# N32MC47x_DP47x register map
Vendor: Nsingtech Ltd.; File version: 1.0
Registers are 32-bit, read-write, reset 0x0 unless marked. A register's access mark holds for its fields unless they carry their own. Offsets are from the block's base; [hi:lo] are bit positions.

## USART1
Base 0x40011C00
Same registers: USART2 0x40000C00, USART3 0x40001000, UART8 0x40001400, UART5 0x40006800, UART6 0x40012000, UART7 0x40012400, USART4 0x40012800
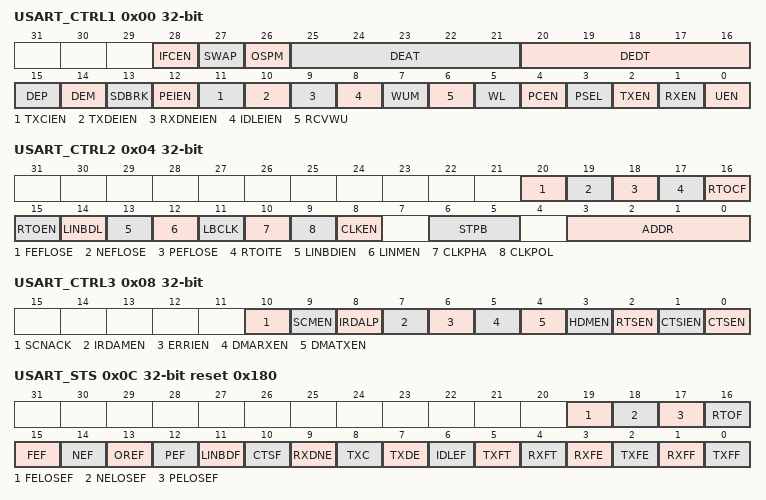
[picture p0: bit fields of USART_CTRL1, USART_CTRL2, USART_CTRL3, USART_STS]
0x00 USART_CTRL1
  [28] IFCEN, [27] SWAP, [26] OSPM, [25:21] DEAT, [20:16] DEDT, [15] DEP, [14] DEM, [13] SDBRK, [12] PEIEN, [11] TXCIEN, [10] TXDEIEN, [9] RXDNEIEN, [8] IDLEIEN, [7] WUM, [6] RCVWU, [5] WL, [4] PCEN, [3] PSEL, [2] TXEN, [1] RXEN, [0] UEN
0x04 USART_CTRL2
  [20] FEFLOSE, [19] NEFLOSE, [18] PEFLOSE, [17] RTOITE, [16] RTOCF, [15] RTOEN, [14] LINBDL, [13] LINBDIEN, [12] LINMEN, [11] LBCLK, [10] CLKPHA, [9] CLKPOL, [8] CLKEN, [6:5] STPB, [3:0] ADDR
0x08 USART_CTRL3
  [10] SCNACK, [9] SCMEN, [8] IRDALP, [7] IRDAMEN, [6] ERRIEN, [5] DMARXEN, [4] DMATXEN, [3] HDMEN, [2] RTSEN, [1] CTSIEN, [0] CTSEN
0x0C USART_STS reset 0x180
  [19] FELOSEF, [18] NELOSEF, [17] PELOSEF, [16] RTOF, [15] FEF, [14] NEF, [13] OREF, [12] PEF, [11] LINBDF, [10] CTSF, [9] RXDNE, [8] TXC, [7] TXDE, [6] IDLEF, [5] TXFT, [4] RXFT, [3] RXFE, [2] TXFE, [1] RXFF, [0] TXFF
0x10 USART_DAT
  [8:0] DATV
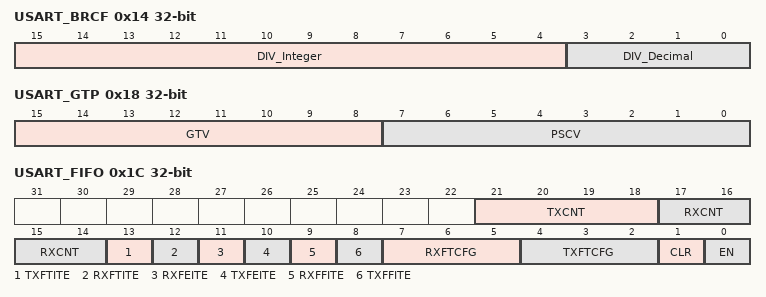
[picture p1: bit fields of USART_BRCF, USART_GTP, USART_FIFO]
0x14 USART_BRCF
  [15:4] DIV_Integer, [3:0] DIV_Decimal
0x18 USART_GTP
  [15:8] GTV, [7:0] PSCV
0x1C USART_FIFO
  [21:18] TXCNT, [17:14] RXCNT, [13] TXFTITE, [12] RXFTITE, [11] RXFEITE, [10] TXFEITE, [9] RXFFITE, [8] TXFFITE, [7:5] RXFTCFG, [4:2] TXFTCFG, [1] CLR, [0] EN
0x20 USART_IFW
  [15:0] WIDTH
0x24 USART_RTO
  [27:0] TIME

## DAC12
Base 0x40007C00
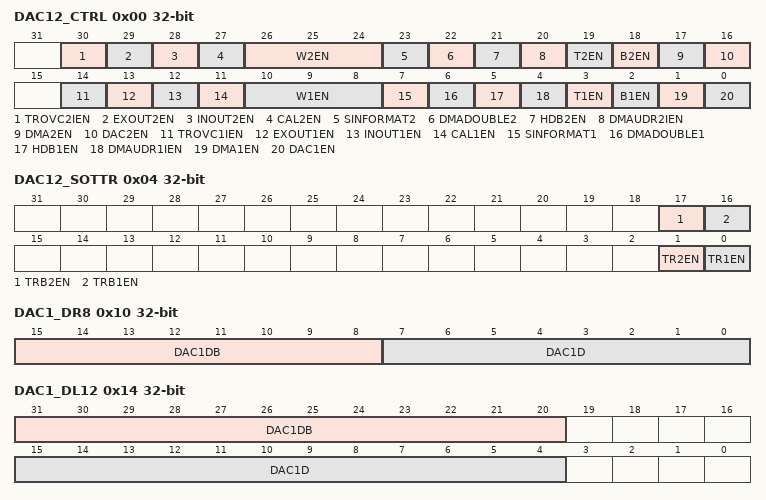
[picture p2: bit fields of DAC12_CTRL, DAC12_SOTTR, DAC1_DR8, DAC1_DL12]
0x00 DAC12_CTRL
  [30] TROVC2IEN, [29] EXOUT2EN, [28] INOUT2EN, [27] CAL2EN, [26:24] W2EN, [23] SINFORMAT2, [22] DMADOUBLE2, [21] HDB2EN, [20] DMAUDR2IEN, [19] T2EN, [18] B2EN, [17] DMA2EN, [16] DAC2EN, [14] TROVC1IEN, [13] EXOUT1EN, [12] INOUT1EN, [11] CAL1EN, [10:8] W1EN, [7] SINFORMAT1, [6] DMADOUBLE1, [5] HDB1EN, [4] DMAUDR1IEN, [3] T1EN, [2] B1EN, [1] DMA1EN, [0] DAC1EN
0x04 DAC12_SOTTR
  [17] TRB2EN, [16] TRB1EN, [1] TR2EN, [0] TR1EN
0x08 DAC1_DATO
  [11:0] DAC1DO
0x0C DAC2_DATO
  [11:0] DAC2DO
0x10 DAC1_DR8
  [15:8] DAC1DB, [7:0] DAC1D
0x14 DAC1_DL12
  [31:20] DAC1DB, [15:4] DAC1D
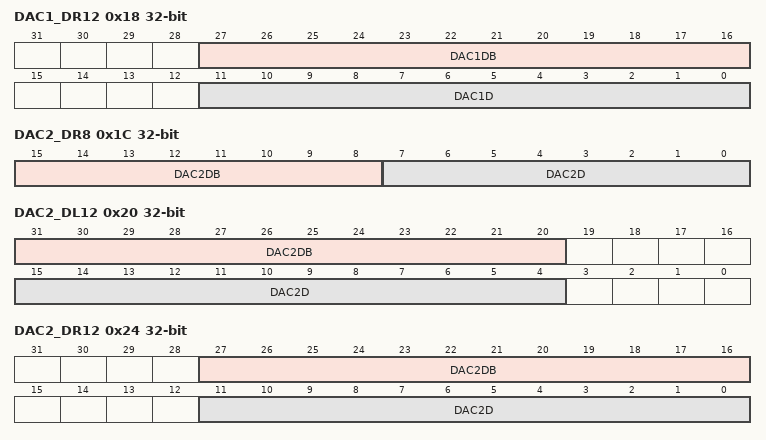
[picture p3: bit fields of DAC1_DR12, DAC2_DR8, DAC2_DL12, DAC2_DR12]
0x18 DAC1_DR12
  [27:16] DAC1DB, [11:0] DAC1D
0x1C DAC2_DR8
  [15:8] DAC2DB, [7:0] DAC2D
0x20 DAC2_DL12
  [31:20] DAC2DB, [15:4] DAC2D
0x24 DAC2_DR12
  [27:16] DAC2DB, [11:0] DAC2D
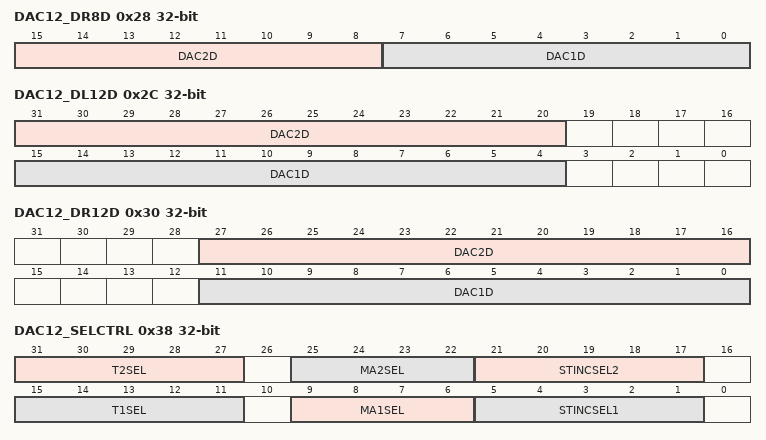
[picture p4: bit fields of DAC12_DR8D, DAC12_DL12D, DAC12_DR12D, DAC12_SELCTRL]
0x28 DAC12_DR8D
  [15:8] DAC2D, [7:0] DAC1D
0x2C DAC12_DL12D
  [31:20] DAC2D, [15:4] DAC1D
0x30 DAC12_DR12D
  [27:16] DAC2D, [11:0] DAC1D
0x38 DAC12_SELCTRL
  [31:27] T2SEL, [25:22] MA2SEL, [21:17] STINCSEL2, [15:11] T1SEL, [9:6] MA1SEL, [5:1] STINCSEL1
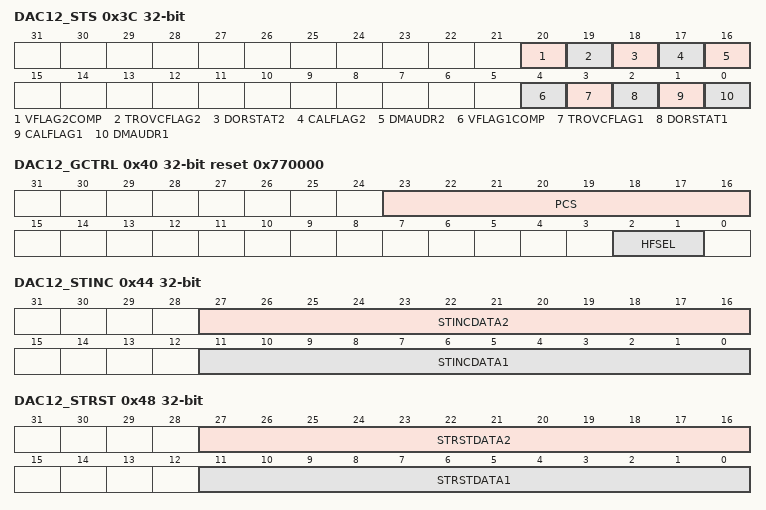
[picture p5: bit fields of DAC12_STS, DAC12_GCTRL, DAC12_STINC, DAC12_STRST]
0x3C DAC12_STS
  [20] VFLAG2COMP, [19] TROVCFLAG2, [18] DORSTAT2, [17] CALFLAG2, [16] DMAUDR2, [4] VFLAG1COMP, [3] TROVCFLAG1, [2] DORSTAT1, [1] CALFLAG1, [0] DMAUDR1
0x40 DAC12_GCTRL reset 0x770000
  [23:16] PCS, [2:1] HFSEL
0x44 DAC12_STINC
  [27:16] STINCDATA2, [11:0] STINCDATA1
0x48 DAC12_STRST
  [27:16] STRSTDATA2, [11:0] STRSTDATA1
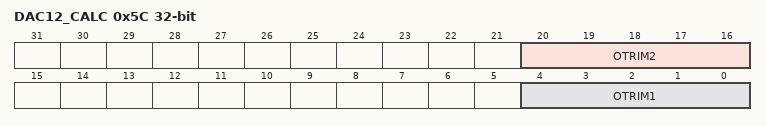
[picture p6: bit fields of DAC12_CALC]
0x5C DAC12_CALC
  [20:16] OTRIM2, [4:0] OTRIM1

## DAC34
Base 0x40008000
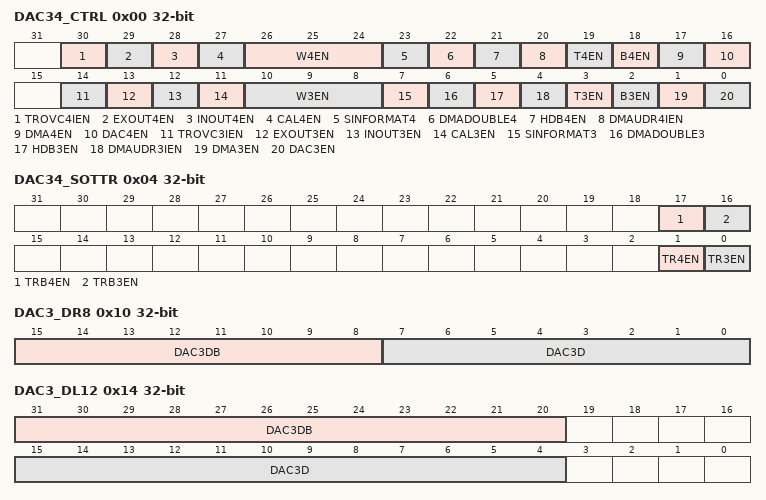
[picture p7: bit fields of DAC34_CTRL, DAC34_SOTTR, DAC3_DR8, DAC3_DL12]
0x00 DAC34_CTRL
  [30] TROVC4IEN, [29] EXOUT4EN, [28] INOUT4EN, [27] CAL4EN, [26:24] W4EN, [23] SINFORMAT4, [22] DMADOUBLE4, [21] HDB4EN, [20] DMAUDR4IEN, [19] T4EN, [18] B4EN, [17] DMA4EN, [16] DAC4EN, [14] TROVC3IEN, [13] EXOUT3EN, [12] INOUT3EN, [11] CAL3EN, [10:8] W3EN, [7] SINFORMAT3, [6] DMADOUBLE3, [5] HDB3EN, [4] DMAUDR3IEN, [3] T3EN, [2] B3EN, [1] DMA3EN, [0] DAC3EN
0x04 DAC34_SOTTR
  [17] TRB4EN, [16] TRB3EN, [1] TR4EN, [0] TR3EN
0x08 DAC3_DATO
  [11:0] DAC3DO
0x0C DAC4_DATO
  [11:0] DAC4DO
0x10 DAC3_DR8
  [15:8] DAC3DB, [7:0] DAC3D
0x14 DAC3_DL12
  [31:20] DAC3DB, [15:4] DAC3D
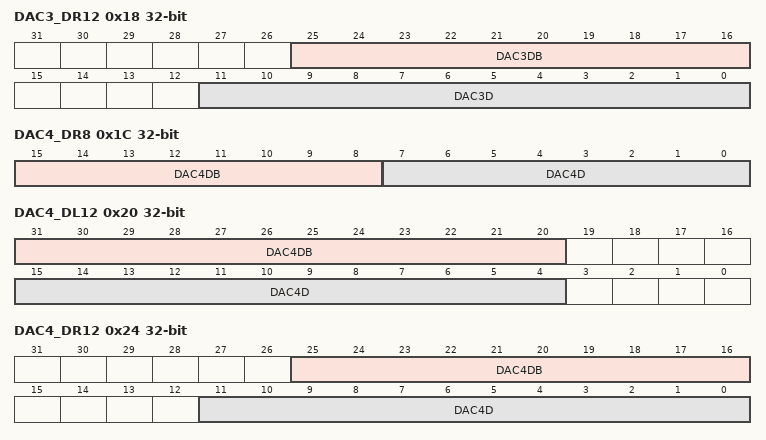
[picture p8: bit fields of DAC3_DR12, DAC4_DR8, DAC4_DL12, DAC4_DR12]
0x18 DAC3_DR12
  [25:16] DAC3DB, [11:0] DAC3D
0x1C DAC4_DR8
  [15:8] DAC4DB, [7:0] DAC4D
0x20 DAC4_DL12
  [31:20] DAC4DB, [15:4] DAC4D
0x24 DAC4_DR12
  [25:16] DAC4DB, [11:0] DAC4D
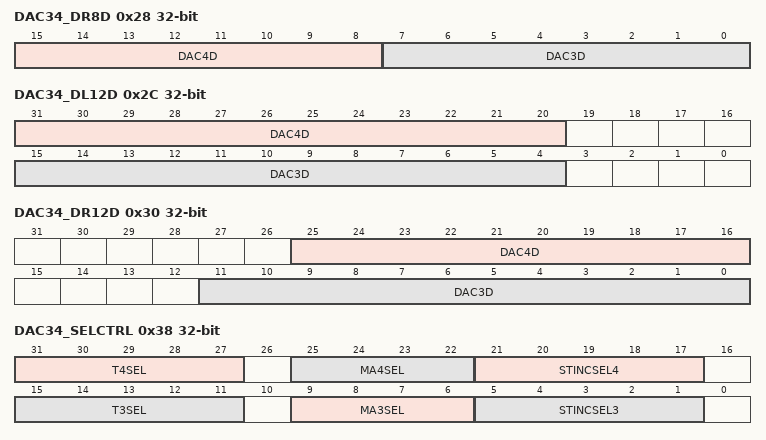
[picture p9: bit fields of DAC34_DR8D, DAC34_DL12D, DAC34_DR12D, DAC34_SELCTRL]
0x28 DAC34_DR8D
  [15:8] DAC4D, [7:0] DAC3D
0x2C DAC34_DL12D
  [31:20] DAC4D, [15:4] DAC3D
0x30 DAC34_DR12D
  [25:16] DAC4D, [11:0] DAC3D
0x38 DAC34_SELCTRL
  [31:27] T4SEL, [25:22] MA4SEL, [21:17] STINCSEL4, [15:11] T3SEL, [9:6] MA3SEL, [5:1] STINCSEL3
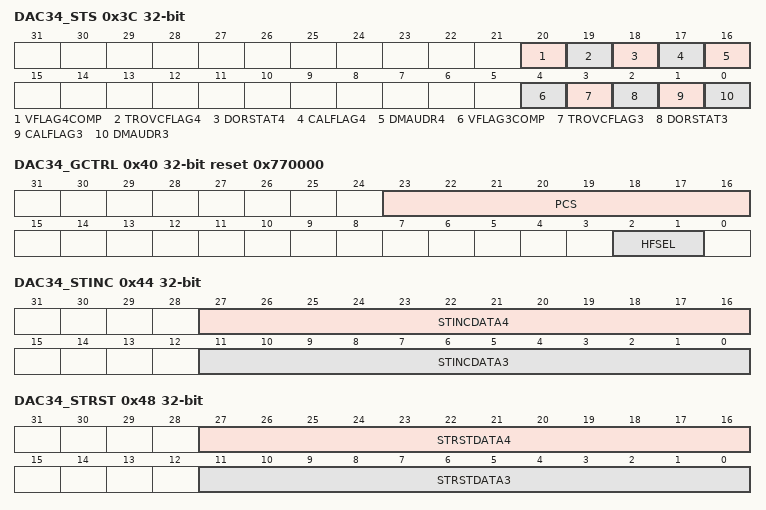
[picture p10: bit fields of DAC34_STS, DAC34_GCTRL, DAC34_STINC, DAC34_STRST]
0x3C DAC34_STS
  [20] VFLAG4COMP, [19] TROVCFLAG4, [18] DORSTAT4, [17] CALFLAG4, [16] DMAUDR4, [4] VFLAG3COMP, [3] TROVCFLAG3, [2] DORSTAT3, [1] CALFLAG3, [0] DMAUDR3
0x40 DAC34_GCTRL reset 0x770000
  [23:16] PCS, [2:1] HFSEL
0x44 DAC34_STINC
  [27:16] STINCDATA4, [11:0] STINCDATA3
0x48 DAC34_STRST
  [27:16] STRSTDATA4, [11:0] STRSTDATA3
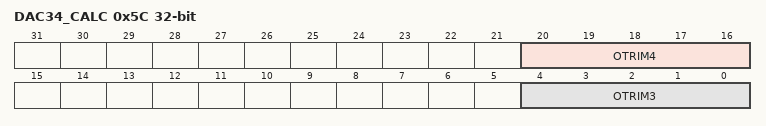
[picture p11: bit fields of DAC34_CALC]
0x5C DAC34_CALC
  [20:16] OTRIM4, [4:0] OTRIM3
